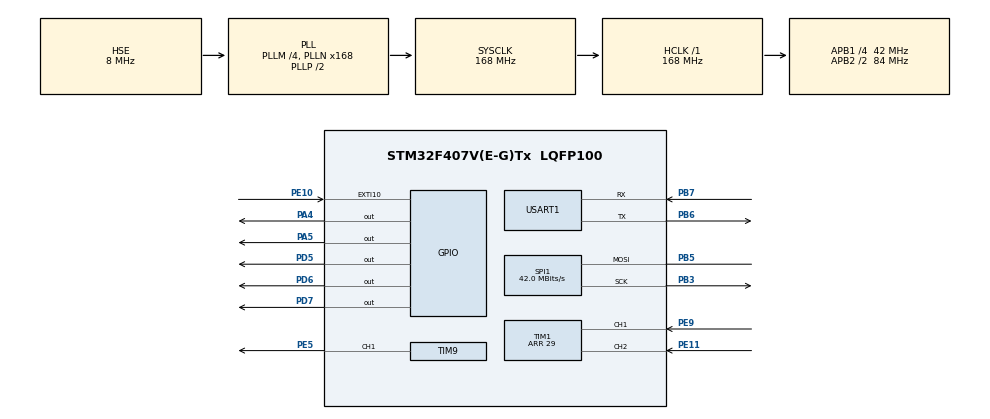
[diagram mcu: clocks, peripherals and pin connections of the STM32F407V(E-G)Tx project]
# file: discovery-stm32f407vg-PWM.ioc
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Mcu.Family=STM32F4
Dma.TIM8_CH1.0.Direction=DMA_MEMORY_TO_PERIPH
PH0-OSC_IN.Signal=RCC_OSC_IN
TIM8.ClockDivision=TIM_CLOCKDIVISION_DIV1
RCC.CortexFreq_Value=168000000
SPI1.VirtualType=VM_MASTER
RCC.SYSCLKSource=RCC_SYSCLKSOURCE_PLLCLK
ProjectManager.StackSize=0x400
SPI1.Direction=SPI_DIRECTION_1LINE
RCC.HCLKFreq_Value=168000000
RCC.APB2TimFreq_Value=168000000
PB6.Signal=USART1_TX
PB6.Mode=Asynchronous
SPI1.CalculateBaudRate=42.0 MBits/s
PE5.Signal=S_TIM9_CH1
Dma.TIM8_CH1.0.MemDataAlignment=DMA_MDATAALIGN_WORD
RCC.AHBFreq_Value=168000000
PH0-OSC_IN.Mode=HSE-External-Oscillator
RCC.HSE_VALUE=8000000
PB3.Mode=Simplex_Bidirectional_Master
TIM8.Channel-Output\ Compare1\ No\ Output=TIM_CHANNEL_1
PE9.Signal=S_TIM1_CH1
PA14.Mode=Serial_Wire
PB5.Mode=Simplex_Bidirectional_Master
PB7.Signal=USART1_RX
PE10.Signal=GPXTI10
TIM9.Prescaler=0
PH1-OSC_OUT.Mode=HSE-External-Oscillator
Mcu.Package=LQFP100
TIM8.Prescaler=0
RCC.APB2CLKDivider=RCC_HCLK_DIV2
NVIC.DMA2_Stream2_IRQn=true\:0\:0\:false\:false\:true\:false\:true
RCC.APB1TimFreq_Value=84000000
TIM1.Period=29
PD6.Signal=GPIO_Output
Dma.Request0=TIM8_CH1
TIM9.Period=512-1
RCC.PLLSourceVirtual=RCC_PLLSOURCE_HSE
TIM9.Channel-PWM\ Generation1\ CH1=TIM_CHANNEL_1
PD7.Signal=GPIO_Output
PD5.Signal=GPIO_Output
RCC.APB1CLKDivider=RCC_HCLK_DIV4
Dma.TIM8_CH1.0.PeriphDataAlignment=DMA_PDATAALIGN_WORD
PA13.Signal=SYS_JTMS-SWDIO
Dma.TIM8_CH1.0.Priority=DMA_PRIORITY_VERY_HIGH
SH.S_TIM1_CH1.0=TIM1_CH1,Encoder_Interface
ProjectManager.TargetToolchain=STM32CubeIDE
VP_TIM8_VS_ClockSourceINT.Mode=Internal
PE11.Signal=S_TIM1_CH2
RCC.LSE_VALUE=32768
PA5.Signal=GPIO_Output
VP_TIM8_VS_no_output1.Mode=Output Compare1 No Output
TIM8.AutoReloadPreload=TIM_AUTORELOAD_PRELOAD_ENABLE
board=custom
RCC.VCOOutputFreq_Value=336000000
Dma.TIM8_CH1.0.MemInc=DMA_MINC_ENABLE
TIM9.AutoReloadPreload=TIM_AUTORELOAD_PRELOAD_ENABLE
VP_TIM9_VS_ClockSourceINT.Mode=Internal
RCC.APB2Freq_Value=84000000
SH.S_TIM1_CH2.0=TIM1_CH2,Encoder_Interface
SPI1.Mode=SPI_MODE_MASTER
Dma.TIM8_CH1.0.Mode=DMA_CIRCULAR
SH.S_TIM9_CH1.0=TIM9_CH1,PWM Generation1 CH1
PH1-OSC_OUT.Signal=RCC_OSC_OUT
PA13.Mode=Serial_Wire
Dma.TIM8_CH1.0.Instance=DMA2_Stream2
Mcu.Name=STM32F407V(E-G)Tx
TIM9.ClockDivision=TIM_CLOCKDIVISION_DIV1
TIM8.Period=100
RCC.48MHZClocksFreq_Value=84000000
PB3.Signal=SPI1_SCK
PA4.Signal=GPIO_Output
RCC.SYSCLKFreq_VALUE=168000000
PB5.Signal=SPI1_MOSI
USART1.VirtualMode=VM_ASYNC
PB7.Mode=Asynchronous
PA14.Signal=SYS_JTCK-SWCLK
ProjectManager.HeapSize=0x200
Dma.TIM8_CH1.0.FIFOMode=DMA_FIFOMODE_DISABLE
RCC.HSI_VALUE=16000000
NVIC.PriorityGroup=NVIC_PRIORITYGROUP_4
RCC.PLLM=4
RCC.PLLN=168
Dma.TIM8_CH1.0.PeriphInc=DMA_PINC_DISABLE
RCC.APB1Freq_Value=42000000

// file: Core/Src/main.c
/* USER CODE BEGIN Header */
/**
  ******************************************************************************
  * @file           : main.c
  * @brief          : Main program body
  ******************************************************************************
  * @attention
  *
  * <h2><center>&copy; Copyright (c) 2021 STMicroelectronics.
  * All rights reserved.</center></h2>
  *
  * This software component is licensed by ST under BSD 3-Clause license,
  * the "License"; You may not use this file except in compliance with the
  * License. You may obtain a copy of the License at:
  *                        opensource.org/licenses/BSD-3-Clause
  *
  ******************************************************************************
  */
/* USER CODE END Header */
#include "main.h"
#include "dma.h"
#include "spi.h"
#include "tim.h"
#include "usart.h"
#include "gpio.h"

/* USER CODE BEGIN Includes */
#include "waveform_gen.h"
/* USER CODE END Includes */

/* USER CODE BEGIN PD */
#define TIM8CLK  168000000
//#define TIM4CLK  84000000
#define F_SIGNAL 5000
/* USER CODE END PD */

/* USER CODE BEGIN PV */

uint32_t DestAddress = (uint32_t) &(TIM9->CCR1);
uint64_t TIM8_Ticks = TIM8CLK / (N_s * F_SIGNAL);

//uint32_t DestAddress = (uint32_t) &(TIM2->CCR1);
//uint64_t TIM4_Ticks = TIM4CLK / (NS * F_SIGNAL);

//uint32_t DestAddress = (uint32_t) &(TIM9->CCR1);
//uint64_t TIM8_Ticks = TIM8CLK / (NS * F_SIGNAL);
/* USER CODE END PV */

void SystemClock_Config(void);

int main(void)
{

  /* MCU Configuration--------------------------------------------------------*/

  /* Reset of all peripherals, Initializes the Flash interface and the Systick. */
  HAL_Init();

  /* Configure the system clock */
  SystemClock_Config();

  /* Initialize all configured peripherals */
  MX_GPIO_Init();
  MX_DMA_Init();
  MX_SPI1_Init();
  MX_TIM1_Init();
  MX_USART1_UART_Init();
  MX_TIM8_Init();
  MX_TIM9_Init();
  /* USER CODE BEGIN 2 */
  HAL_TIM_PWM_Start(&htim9, TIM_CHANNEL_1);
  HAL_TIM_OC_Start(&htim8, TIM_CHANNEL_1);
  HAL_DMA_Start_IT(&hdma_tim8_ch1, (uint32_t)sine_val, DestAddress, N_s);
  __HAL_TIM_ENABLE_DMA(&htim8, TIM_DMA_CC1);

//  HAL_TIM_PWM_Start(&htim2, TIM_CHANNEL_1);
//  HAL_TIM_OC_Start(&htim4, TIM_CHANNEL_1);
//  HAL_DMA_Start_IT(&hdma_tim4_ch1, (uint32_t)Wave_LUT, DestAddress, NS);
//  __HAL_TIM_ENABLE_DMA(&htim4, TIM_DMA_CC1);
  /* USER CODE END 2 */

  /* Infinite loop */
  while (1)
  {

  }
}

void SystemClock_Config(void)
{
  RCC_OscInitTypeDef RCC_OscInitStruct = {0};
  RCC_ClkInitTypeDef RCC_ClkInitStruct = {0};

  /** Configure the main internal regulator output voltage
  */
  __HAL_RCC_PWR_CLK_ENABLE();
  __HAL_PWR_VOLTAGESCALING_CONFIG(PWR_REGULATOR_VOLTAGE_SCALE1);
  /** Initializes the RCC Oscillators according to the specified parameters
  * in the RCC_OscInitTypeDef structure.
  */
  RCC_OscInitStruct.OscillatorType = RCC_OSCILLATORTYPE_HSE;
  RCC_OscInitStruct.HSEState = RCC_HSE_ON;
  RCC_OscInitStruct.PLL.PLLState = RCC_PLL_ON;
  RCC_OscInitStruct.PLL.PLLSource = RCC_PLLSOURCE_HSE;
  RCC_OscInitStruct.PLL.PLLM = 4;
  RCC_OscInitStruct.PLL.PLLN = 168;
  RCC_OscInitStruct.PLL.PLLP = RCC_PLLP_DIV2;
  RCC_OscInitStruct.PLL.PLLQ = 4;
  if (HAL_RCC_OscConfig(&RCC_OscInitStruct) != HAL_OK)
  {
    Error_Handler();
  }
  /** Initializes the CPU, AHB and APB buses clocks
  */
  RCC_ClkInitStruct.ClockType = RCC_CLOCKTYPE_HCLK|RCC_CLOCKTYPE_SYSCLK
                              |RCC_CLOCKTYPE_PCLK1|RCC_CLOCKTYPE_PCLK2;
  RCC_ClkInitStruct.SYSCLKSource = RCC_SYSCLKSOURCE_PLLCLK;
  RCC_ClkInitStruct.AHBCLKDivider = RCC_SYSCLK_DIV1;
  RCC_ClkInitStruct.APB1CLKDivider = RCC_HCLK_DIV4;
  RCC_ClkInitStruct.APB2CLKDivider = RCC_HCLK_DIV2;

  if (HAL_RCC_ClockConfig(&RCC_ClkInitStruct, FLASH_LATENCY_5) != HAL_OK)
  {
    Error_Handler();
  }
}

void Error_Handler(void)
{
  __disable_irq();
  while (1)
  {
  }
}

/************************ (C) COPYRIGHT STMicroelectronics *****END OF FILE****/
